# RN831X_RN861X_MCU register map
File version: v0.0.1
CPU: RN831X_RN861X_MCU r1p0, little endian, MPU, no FPU
Registers are 32-bit, read-write, reset 0x0 unless marked. A register's access mark holds for its fields unless they carry their own. Offsets are from the block's base; [hi:lo] are bit positions; {n}, {i} and the like mark numbered series; 'fields as' and 'values as' point back to an identical list.

## KBI0_CORE0 — KBI0 Module core0
Base 0x20064000
Same registers: KBI1_CORE0 0x20068000, KBI0_CORE1 0xA0064000, KBI1_CORE1 0xA0068000
0x00 CTRL access not given — Control Register
  [15:0] EN — Enable/Disable KBI channel
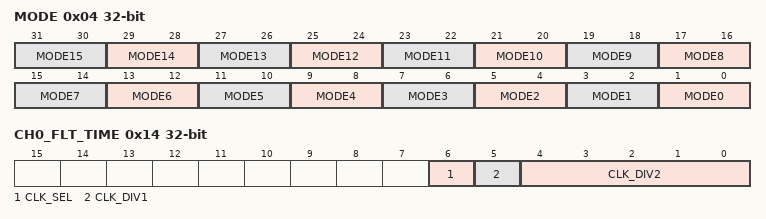
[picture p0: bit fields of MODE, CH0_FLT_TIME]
0x04 MODE
  [all] fields
    0=RISING (Trigger Rising Edge Mode); 1=FALLING (Trigger Falling Edge Mode); 2=RISING_FALLING (Trigger Rising & Falling Edge Mode)
  [2n+1:2n] MODE{n} (n=0..15) — KBI channel {n} interrupt input valid mode selection
0x0C MASK access not given
  [15:0] MASK — Enable/Disable KBI channel interrupt
0x10 STA access not given — Interrupt status Register
  [15:0] STA — Flag for KBI channel interrupt
0x14 CH0_FLT_TIME — Channel 0 Filtering time configure Register
  [6] CLK_SEL — Filter clock selection
  [5] CLK_DIV1 — Filter clock first-level frequency division
  [4:0] CLK_DIV2 — Filter clock second-level frequency division, if set to 0, it means turning off the channel input filter
{0x14+4i} CH{i}_FLT_TIME {i+32}-bit (i=1..15) — Channel {i} Filtering time configure Register
  fields as CH0_FLT_TIME

## KEYSTORE_CORE0 — KeyStore Module
Base 0x3000A000
Same registers: KEYSTORE_CORE1 0xB000A000
0x00 CTRL — KeyStore Control Register.
  [2:0] OPMODE — Set KeyStore different operation mode
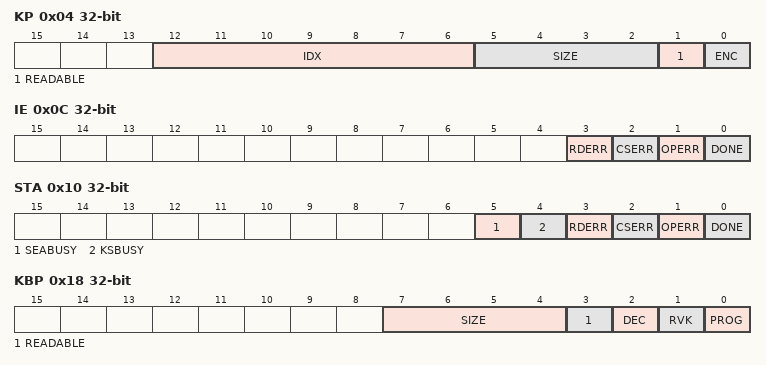
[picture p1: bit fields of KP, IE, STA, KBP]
0x04 KP — KeyStore Key Parameter Register.
  [12:6] IDX — Set the creating key index in KeyStore.
  [5:2] SIZE — Set the key length.
    0=KLEN128 (128-bit key.); 1=KLEN160 (160-bit key.); 2=KLEN192 (192-bit key.); 3=KLEN224 (224-bit key.); 4=KLEN256 (256-bit key.); 5=KLEN384 (384-bit key.); 6=KLEN512 (512-bit key.); 7=KLEN521 (521-bit key.); 8=KLEN576 (576-bit key.)
  [1] READABLE — Set whether the key is readable.
  [0] ENC — Enable encryption in creating key.
0x08 ENC — KeyStore Encrypt Parameter Register.
  [6:0] IDX — The index of key due to encrypt
0x0C IE — KeyStore Interrupt Enable Register.
  [3] RDERR — Enable KS operation read error interrupt
  [2] CSERR — Enable KS operation verify error interrupt
  [1] OPERR — Enable KS operation error interrupt
  [0] DONE — Enable KS operation complete interrupt
0x10 STA — KeyStore Status Register.
  [5] SEABUSY ro — SEA busy flag.
  [4] KSBUSY ro — KeyStore busy flag.
  [3] RDERR write-1-clears — KeyStore read error interrupt flag.
  [2] CSERR write-1-clears — KeyStore verify error interrupt flag.
  [1] OPERR write-1-clears — KeyStore operation error interrupt flag.
  [0] DONE write-1-clears — KeyStore operation complete interrupt flag.
0x14 START — KeyStore Start Register.
  [0] EN — Enable KeyStore running
0x18 KBP ro — KeyStore Key Block Register.
  [7:4] SIZE — The key length in bits.
    values as KP.SIZE
  [3] READABLE — Whether the key slot is readable to CPU.
  [2] DEC — Whether the key slot is encrypted.
  [1] RVK — Whether the key slot is revoked.
  [0] PROG — Whether the key slot is programmed.
0x1C ENCMODE — KeyStore Encrypt Mode Register.
  [0] MODE — Set KeyStore encrypt mode
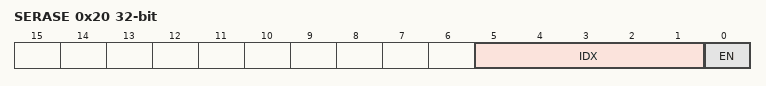
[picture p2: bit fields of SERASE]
0x20 SERASE — KeyStore Sector Erase Register.
  [5:1] IDX — Select the sector index: 6~8, other is invalid.
  [0] EN — Enable erase sector.
{0x30+4i} KEY{i} (i=0..17) — KeyStore Key Storage Registers.
  [31:0] BUF — Key Buffer

## LCSS_VBAT_CORE0 — LCSS_VBAT Module core0
Base 0x200B8200
Same registers: LCSS_VBAT_CORE1 0xB00B8200
0x00 PSW0 access not given — Security key register 0
  [15:0] PSW0 — Managed registers include LCSS_VBAT_EN/LCSS_CTRL/LCSS_IE
0x04 PSW1 access not given — Security key register 1
  [15:0] PSW1 — Managed registers include LCSS_CLKSWH
0x08 EN access not given — Enable register
  [0] EN — LCSS VBAT enable
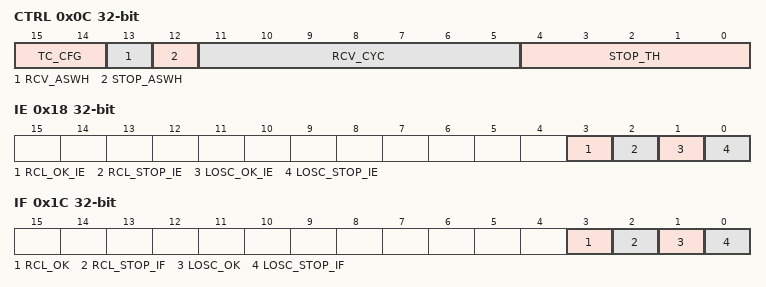
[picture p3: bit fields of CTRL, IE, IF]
0x0C CTRL — Control register
  [15:14] TC_CFG — Timing detection function configuration
    0=TIMING_NONE (No timing detection); 1=TIMING_10MS (10ms timing detection, start detection every 10ms); 2=TIMING_20MS (20ms timing detection, start detection every 20ms); 3=TIMING_40MS (40ms timing detection, start detection every 40ms)
  [13] RCV_ASWH — Auto switch when clock recovery
  [12] STOP_ASWH — Auto switch when clock stopped
  [11:5] RCV_CYC — LOSC recovery cycles configuration
  [4:0] STOP_TH — Clock stop threshold configuration
0x10 CLKSWH wo reset 0x1 — Clock configuration register for software switch
  [2:0] RTC_CLK_SWH — Clock source selection
    1=LOSC (Selected LOSC clock); 2=RCL (Selected RCL32k clock); 4=RCO (Selected RCO clock)
0x14 CLKSEL wo reset 0x1 — Clock selected register, indicate the selected clock
  [2:0] RTC_CLK_SEL — Clock source selection, this register must be written to 0 before reading to read the latest value.
    values as CLKSWH.RTC_CLK_SWH
0x18 IE — Interrupt enable register
  [3] RCL_OK_IE — RCL is ok interrupt enable
  [2] RCL_STOP_IE — RCL stopped interrupt enable
  [1] LOSC_OK_IE — LOSC is ok interrupt enable
  [0] LOSC_STOP_IE — LOSC stopped interrupt enable
0x1C IF — Status register
  [3] RCL_OK write-1-clears — RCL is ok status, when LCSS_VBAT_EN=0, the state will not be automatically updated (this bit must be written 1 twice to clear)
  [2] RCL_STOP_IF write-1-clears — RCL stopped status, when LCSS_VBAT_EN=0, the state will not be automatically updated (this bit must be written 1 twice to clear)
  [1] LOSC_OK write-1-clears — LOSC is ok status, when LCSS_VBAT_EN=0, the state will not be automatically updated (this bit must be written 1 twice to clear)
  [0] LOSC_STOP_IF write-1-clears — LOSC stopped status, when LCSS_VBAT_EN=0, the state will not be automatically updated (this bit must be written 1 twice to clear)
